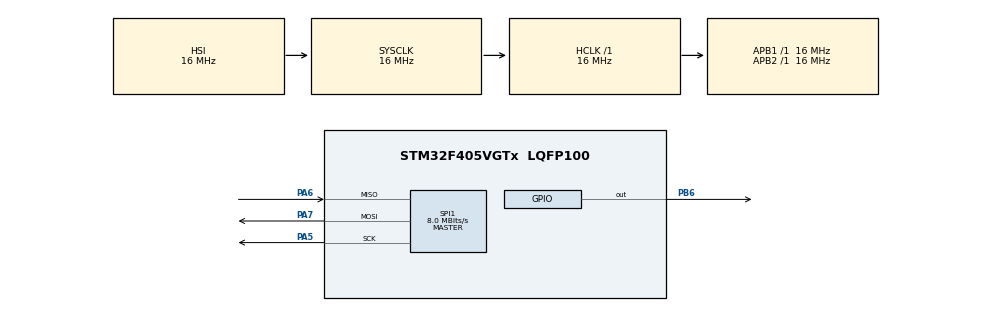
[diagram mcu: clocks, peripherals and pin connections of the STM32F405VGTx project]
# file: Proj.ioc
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Mcu.Family=STM32F4
Mcu.Name=STM32F405VGTx
Mcu.Package=LQFP100
NVIC.PriorityGroup=NVIC_PRIORITYGROUP_4
PA5.Mode=Full_Duplex_Master
PA5.Signal=SPI1_SCK
PA6.Mode=Full_Duplex_Master
PA6.Signal=SPI1_MISO
PA7.Mode=Full_Duplex_Master
PA7.Signal=SPI1_MOSI
PB6.Signal=GPIO_Output
ProjectManager.HeapSize=0x200
ProjectManager.StackSize=0x400
ProjectManager.TargetToolchain=TrueSTUDIO
RCC.AHBFreq_Value=16000000
RCC.APB1Freq_Value=16000000
RCC.APB2Freq_Value=16000000
RCC.CortexFreq_Value=16000000
RCC.HSE_VALUE=25000000
RCC.HSI_VALUE=16000000
RCC.LSE_VALUE=32768
RCC.SYSCLKFreq_VALUE=16000000
RCC.VCOOutputFreq_Value=192000000
SPI1.CalculateBaudRate=8.0 MBits/s
SPI1.Direction=SPI_DIRECTION_2LINES
SPI1.Mode=SPI_MODE_MASTER
SPI1.VirtualType=VM_MASTER
board=custom

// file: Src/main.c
/* USER CODE BEGIN Header */
/**
  ******************************************************************************
  * @file           : main.c
  * @brief          : Main program body
  ******************************************************************************
  * @attention
  *
  * <h2><center>&copy; Copyright (c) 2020 STMicroelectronics.
  * All rights reserved.</center></h2>
  *
  * This software component is licensed by ST under BSD 3-Clause license,
  * the "License"; You may not use this file except in compliance with the
  * License. You may obtain a copy of the License at:
  *                        opensource.org/licenses/BSD-3-Clause
  *
  ******************************************************************************
  */
/* USER CODE END Header */

#include "main.h"

/* USER CODE BEGIN Includes */
#include "socket.h"
/* USER CODE END Includes */

SPI_HandleTypeDef hspi1;

void SystemClock_Config(void);
static void MX_GPIO_Init(void);
static void MX_SPI1_Init(void);

/* USER CODE BEGIN 0 */
// простой tcp сервер. Данные не принимаем, только посылаем строчку Hello World.
// вы можете самостоятельно дополнить функцию для получения данных от клиента
void tcp_server()
{
  uint8_t retVal, sockStatus;

  // а вот это как раз моя функция вывода сообщений через модуль UART-USB
  // если вместо -1 поставить число, она и его отобразит.
  // в недрах этой функции работающая строка будет
  // HAL_UART_Transmit(&huart1, (uint8_t*)buf, strlen(buf), 0xFFFF);
//  trace(-1,"Try open socket\r\n");

  // открываем сокет 0 как TCP_SOCKET, порт 5000 */
  if((retVal = socket(0, Sn_MR_TCP, 5000, 0)) != 0)
  {
    //trace(-1, "Error open socket\r\n");
    return;
  }
//  trace(-1,"Socket opened, try listen\r\n");
//
//  // устанавливаем сокет в режим LISTEN. Так будет создан tcp сервер
//  if((retVal = listen(0)) != SOCK_OK)
//  {
//    trace(-1, "Error listen socket\r\n");
//    return;
//  }
//
//  trace(-1,"Socked listened, wait for input connection\r\n");
//  // ждем входящих соединений. здесь мы немножко крутимся в бесконечном цикле
//  // и чтобы не заскучать одновременно мигаем светодиодом
//  while((sockStatus = getSn_SR(0)) == SOCK_LISTEN)
//  {
//    HAL_Delay(200);
//    HAL_GPIO_TogglePin(GPIOC, GPIO_PIN_13);
//  }
//
//  // раз мы попали сюда, значит выскочили из цикла. входящее соединение!
//  trace(-1,"Input connection\r\n");
//
//  if((sockStatus = getSn_SR(0)) != SOCK_ESTABLISHED)
//  {
//    trace(-1, "Error socket status\r\n");
//    return;
//  }
//  // из сокета вытаскиваем информацию: кто к нам пришел, откуда
//  // можете также отобразить инфу в трассировке
//  uint8_t remoteIP[4];
//  uint16_t remotePort;
//  getsockopt(0, SO_DESTIP, remoteIP);
//  getsockopt(0, SO_DESTPORT, (uint8_t*)&remotePort);
//
//  // посылаем клиенту приветствие и закрываем сокет
//  if((retVal = send(0, (uint8_t*)MSG, strlen(MSG))) == (int16_t)strlen(MSG))
//    // нехорошо так писать код. TODO: добавить фигурные скобки даже для одной строчки )
//    trace(-1, "Msg sent\r\n");
//  else
//    trace(-1, "Error socket send\r\n");
//
//  // закрываемся. когда нас снова вызовут, мы всегда готовы кработе
//  disconnect(0);
//  close(0);
}
/* USER CODE END 0 */

int main(void)
{

  /* MCU Configuration--------------------------------------------------------*/

  /* Reset of all peripherals, Initializes the Flash interface and the Systick. */
  HAL_Init();

  /* Configure the system clock */
  SystemClock_Config();

  /* Initialize all configured peripherals */
  MX_GPIO_Init();
  MX_SPI1_Init();

  /* Infinite loop */
  while (1)
  {

  }
}

void SystemClock_Config(void)
{
  RCC_OscInitTypeDef RCC_OscInitStruct = {0};
  RCC_ClkInitTypeDef RCC_ClkInitStruct = {0};

  /** Configure the main internal regulator output voltage
  */
  __HAL_RCC_PWR_CLK_ENABLE();
  __HAL_PWR_VOLTAGESCALING_CONFIG(PWR_REGULATOR_VOLTAGE_SCALE1);
  /** Initializes the CPU, AHB and APB busses clocks
  */
  RCC_OscInitStruct.OscillatorType = RCC_OSCILLATORTYPE_HSI;
  RCC_OscInitStruct.HSIState = RCC_HSI_ON;
  RCC_OscInitStruct.HSICalibrationValue = RCC_HSICALIBRATION_DEFAULT;
  RCC_OscInitStruct.PLL.PLLState = RCC_PLL_NONE;
  if (HAL_RCC_OscConfig(&RCC_OscInitStruct) != HAL_OK)
  {
    Error_Handler();
  }
  /** Initializes the CPU, AHB and APB busses clocks
  */
  RCC_ClkInitStruct.ClockType = RCC_CLOCKTYPE_HCLK|RCC_CLOCKTYPE_SYSCLK
                              |RCC_CLOCKTYPE_PCLK1|RCC_CLOCKTYPE_PCLK2;
  RCC_ClkInitStruct.SYSCLKSource = RCC_SYSCLKSOURCE_HSI;
  RCC_ClkInitStruct.AHBCLKDivider = RCC_SYSCLK_DIV1;
  RCC_ClkInitStruct.APB1CLKDivider = RCC_HCLK_DIV1;
  RCC_ClkInitStruct.APB2CLKDivider = RCC_HCLK_DIV1;

  if (HAL_RCC_ClockConfig(&RCC_ClkInitStruct, FLASH_LATENCY_0) != HAL_OK)
  {
    Error_Handler();
  }
}

static void MX_SPI1_Init(void)
{

  /* SPI1 parameter configuration*/
  hspi1.Instance = SPI1;
  hspi1.Init.Mode = SPI_MODE_MASTER;
  hspi1.Init.Direction = SPI_DIRECTION_2LINES;
  hspi1.Init.DataSize = SPI_DATASIZE_8BIT;
  hspi1.Init.CLKPolarity = SPI_POLARITY_LOW;
  hspi1.Init.CLKPhase = SPI_PHASE_1EDGE;
  hspi1.Init.NSS = SPI_NSS_SOFT;
  hspi1.Init.BaudRatePrescaler = SPI_BAUDRATEPRESCALER_2;
  hspi1.Init.FirstBit = SPI_FIRSTBIT_MSB;
  hspi1.Init.TIMode = SPI_TIMODE_DISABLE;
  hspi1.Init.CRCCalculation = SPI_CRCCALCULATION_DISABLE;
  hspi1.Init.CRCPolynomial = 10;
  if (HAL_SPI_Init(&hspi1) != HAL_OK)
  {
    Error_Handler();
  }

}

static void MX_GPIO_Init(void)
{
  GPIO_InitTypeDef GPIO_InitStruct = {0};

  /* GPIO Ports Clock Enable */
  __HAL_RCC_GPIOA_CLK_ENABLE();
  __HAL_RCC_GPIOB_CLK_ENABLE();

  /*Configure GPIO pin Output Level */
  HAL_GPIO_WritePin(GPIOB, GPIO_PIN_6, GPIO_PIN_RESET);

  /*Configure GPIO pin : PB6 */
  GPIO_InitStruct.Pin = GPIO_PIN_6;
  GPIO_InitStruct.Mode = GPIO_MODE_OUTPUT_PP;
  GPIO_InitStruct.Pull = GPIO_NOPULL;
  GPIO_InitStruct.Speed = GPIO_SPEED_FREQ_LOW;
  HAL_GPIO_Init(GPIOB, &GPIO_InitStruct);

}

void Error_Handler(void)
{
}

/************************ (C) COPYRIGHT STMicroelectronics *****END OF FILE****/
